# ATtiny102 device description
Architecture: AVR8L; Family: tinyAVR
Programming and debug interfaces: TPI
Registers are 8-bit, access not given, no defined reset value unless marked. A register's access mark holds for its fields unless they carry their own. Offsets are from the block's base; lines under a group give offsets from that group; [hi:lo] are bit positions; {n}, {i} and the like mark numbered series; 'fields as' and 'values as' point back to an identical list; <NAME> marks a mode.

## Ordering variants
ATtiny102-M7R , ATtiny102F-M7R: UDFN8, pinout SOIC_8, up to 12 MHz, -40 to 105 C, 1.8 to 5.5 V
ATtiny102-SSNR , ATtiny102F-SSNR: SOIC8, pinout SOIC_8, up to 12 MHz, -40 to 105 C, 1.8 to 5.5 V
ATtiny102-M8R , ATtiny102F-M8R: UDFN8, pinout SOIC_8, up to 12 MHz, -40 to 125 C, 1.8 to 5.5 V
ATtiny102-SSFR , ATtiny102F-SSFR: SOIC8, pinout SOIC_8, up to 12 MHz, -40 to 125 C, 1.8 to 5.5 V

## Memory
prog space: start 0x0000 size 0x0400, little endian
  0x0000 FLASH size 0x0400 flash, rw, executable, page 0x80
signatures space: start 0 size 3, little endian
  0 SIGNATURES size 3 signatures, ro
fuses space: start 0 size 0x0001, little endian
  0 FUSES size 0x0001 fuses, rw
lockbits space: start 0 size 0x0001, little endian
  0 LOCKBITS size 0x0001 lockbits, rw
data space: start 0x0000 size 0x4400, little endian
  0x0000 IO size 0x40 io
  0x0040 SRAM size 0x20 ram
  0x3F00 MAPPED_NVM_LOCK_BITS size 0x0002 sysreg
  0x3F40 MAPPED_CONFIGURATION_BITS size 0x0002 sysreg
  0x3F80 MAPPED_CALIBRATION_BITS size 0x0002 sysreg
  0x3FC0 MAPPED_DEVICE_ID_BITS size 0x0004 sysreg
  0x4000 MAPPED_FLASH size 0x0400 other

## Peripheral instances (address, pins/pin function, parameters)
ADC at 0x00 — Analog-to-Digital Converter
  pins: ADC0 PA0; ADC1 PA1; ADC5 PB1; ADC6 PB2; ADC7 PB3
AC at 0x00 — Analog Comparator
  pins: AIN0 PA0/ACIN; AIN1 PA1/ACIN; ACO PB3/ACOUT
CPU at 0x00 — CPU Registers
PORTA at 0x00 — I/O Port
  pins: P0 PA0; P1 PA1; P2 PA2
PORTB at 0x00 — I/O Port
  pins: P1 PB1; P2 PB2; P3 PB3
EXINT at 0x00 — External Interrupts
  pins: PCINT0 PA0/EXTINT; PCINT1 PA1/EXTINT; PCINT2 PA2/EXTINT; PCINT9 PB1/EXTINT; PCINT10 PB2/EXTINT; PCINT11 PB3/EXTINT; INT0 PB1/EXTINT
TC0 at 0x00 — Timer/Counter, 16-bit
  pins: ICP0 PB2/DEF; OC0A PB1/DEF; OC0B PA1/DEF; T0 PA0/DEF
WDT at 0x00 — Watchdog Timer
FUSE at 0 in fuses — Fuses
LOCKBIT at 0 in lockbits — Lockbits
USART at 0
  pins: XCK PB1; TXD PB2; RXD PB3

## Interrupts
0 RESET — External Reset, Power-on Reset and Watchdog Reset
1 INT0 — External Interrupt Request 0
2 PCINT0 — Pin Change Interrupt Request 0
3 PCINT1 — Pin Change Interrupt Request 1
4 TIM0_CAPT — Timer/Counter0 Input Capture
5 TIM0_OVF — Timer/Counter0 Overflow
6 TIM0_COMPA — Timer/Counter Compare Match A
7 TIM0_COMPB — Timer/Counter Compare Match B
8 ANA_COMP — Analog Comparator
9 WDT — Watchdog Time-out
10 VLM — Vcc Voltage Level Monitor
11 ADC — ADC Conversion complete
12 USART_RXS — USART RX Start
13 USART_RXC — USART RX Complete
14 USART_DRE — USART Data register empty
15 USART_TXC — USART Tx Complete

## Properties
SIGNATURES: SIGNATURE0=0x1e, SIGNATURE1=0x90, SIGNATURE2=0x0c
CCP_SIGNATURES: CCP_IOREG_gc=0xD8 (IOREG signature for Change Protect), CCP_SPM_gc=0xE7 (SPM signature for Change Protect)

## Pinouts (pin number, pad)
SOIC_8: 1 VCC, 2 PA0, 3 PA1, 4 PA2, 5 PB1, 6 PB2, 7 PB3, 8 GND

## FUSE — Fuses
Instances: FUSE 0 in fuses
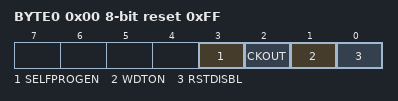
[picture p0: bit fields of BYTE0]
0x00 BYTE0 reset 0xFF
  [3] SELFPROGEN — Self programming enable
  [2] CKOUT — Output external clock
  [1] WDTON — Watch dog timer always on
  [0] RSTDISBL — Disable external reset

## LOCKBIT — Lockbits
Instances: LOCKBIT 0 in lockbits
0x00 LOCKBIT
  [1:0] LB — Memory Lock
    0=PROG_VER_DISABLED (Further programming and verification disabled); 2=PROG_DISABLED (Further programming disabled); 3=NO_LOCK (No memory lock features enabled)

## ADC — Analog-to-Digital Converter
Instances: ADC 0x00
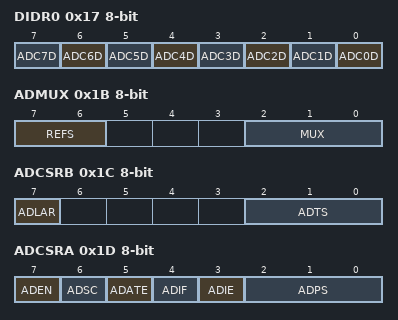
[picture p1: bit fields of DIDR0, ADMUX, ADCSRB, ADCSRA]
0x17 DIDR0 — Digital Input Disable Register
  [n] ADC{n}D (n=0..7) — ADC{n} Digital Input Disable
0x19 ADCL — ADC Data Register Low
0x1A ADCH — ADC Data Register High
0x1B ADMUX — The ADC multiplexer Selection Register
  [7:6] REFS — Analog Reference voltage Selection Bits
    0=Vcc; 1=Internal 1.1V Referemce; 2=Internal 2.2V Referemce; 3=Internal 4.3V Referemce
  [2:0] MUX — Analog Channel Selection Bits
    {v}=ADC{v} (v=0..7)
0x1C ADCSRB — The ADC Control and Status register B
  [7] ADLAR — Left Adjustment for ADC Result Readout
  [2:0] ADTS — ADC Auto Trigger Source bits
    0=Free Running mode; 1=Analog Comparator; 2=External Interrupt Request 0; 3=Timer/Counter0 Compare Match A; 4=Timer/Counter0 Overflow; 5=Timer/Counter0 Compare Match B; 6=Pin Change Interrupt 0 Request; 7=Timer/Counter0 Capture Event
0x1D ADCSRA — The ADC Control and Status register A
  [7] ADEN — ADC Enable
  [6] ADSC — ADC Start Conversion
  [5] ADATE — ADC Auto Trigger Enable
  [4] ADIF — ADC Interrupt Flag
  [3] ADIE — ADC Interrupt Enable
  [2:0] ADPS — ADC Prescaler Select Bits
    0=2; 1=2; 2=4; 3=8; 4=16; 5=32; 6=64; 7=128
